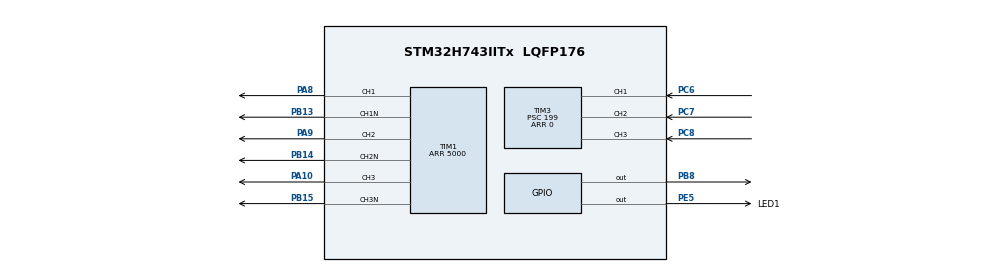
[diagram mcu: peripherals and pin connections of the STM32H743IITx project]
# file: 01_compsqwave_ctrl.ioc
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CORTEX_M7.CPU_DCache=Enabled
CORTEX_M7.CPU_ICache=Enabled
CORTEX_M7.MPU_Control=__NULL
CORTEX_M7.default_mode_Activation=0
Mcu.Family=STM32H7
Mcu.Name=STM32H743IITx
Mcu.Package=LQFP176
NVIC.PriorityGroup=NVIC_PRIORITYGROUP_4
NVIC.TIM3_IRQn=true\:0\:0\:false\:false\:true\:true\:true\:true
PA10.Signal=S_TIM1_CH3
PA13\ (JTMS/SWDIO).Mode=Serial_Wire
PA13\ (JTMS/SWDIO).Signal=DEBUG_JTMS-SWDIO
PA14\ (JTCK/SWCLK).Mode=Serial_Wire
PA14\ (JTCK/SWCLK).Signal=DEBUG_JTCK-SWCLK
PA8.Signal=S_TIM1_CH1
PA9.Signal=S_TIM1_CH2
PB13.Mode=PWM Generation1 CH1 CH1N
PB13.Signal=TIM1_CH1N
PB14.Mode=PWM Generation2 CH2 CH2N
PB14.Signal=TIM1_CH2N
PB15.Mode=PWM Generation3 CH3 CH3N
PB15.Signal=TIM1_CH3N
PB8.Signal=GPIO_Output
PC6.Signal=S_TIM3_CH1
PC7.Signal=S_TIM3_CH2
PC8.Signal=S_TIM3_CH3
PE5.GPIO_Label=LED1
PE5.Signal=GPIO_Output
PH0-OSC_IN\ (PH0).Mode=HSE-External-Oscillator
PH0-OSC_IN\ (PH0).Signal=RCC_OSC_IN
PH1-OSC_OUT\ (PH1).Mode=HSE-External-Oscillator
PH1-OSC_OUT\ (PH1).Signal=RCC_OSC_OUT
ProjectManager.HeapSize=0x200
ProjectManager.StackSize=0x1000
ProjectManager.TargetToolchain=MDK-ARM V5.32
RCC.ADCFreq_Value=50390625
RCC.APB1Freq_Value=100000000
RCC.APB2Freq_Value=100000000
RCC.APB3Freq_Value=100000000
RCC.APB4Freq_Value=100000000
RCC.CortexFreq_Value=400000000
RCC.D1PPRE=RCC_APB3_DIV2
RCC.D2PPRE1=RCC_APB1_DIV2
RCC.D2PPRE2=RCC_APB2_DIV2
RCC.D3PPRE=RCC_APB4_DIV2
RCC.DIVM1=2
RCC.DIVN1=64
RCC.HCLKFreq_Value=200000000
RCC.HPRE=RCC_HCLK_DIV2
RCC.PLLFRACN=0
RCC.PLLSourceVirtual=RCC_PLLSOURCE_HSE
RCC.SYSCLKFreq_VALUE=400000000
RCC.SYSCLKSource=RCC_SYSCLKSOURCE_PLLCLK
RCC.USBFreq_Value=400000000
SH.S_TIM1_CH1.0=TIM1_CH1,PWM Generation1 CH1 CH1N
SH.S_TIM1_CH2.0=TIM1_CH2,PWM Generation2 CH2 CH2N
SH.S_TIM1_CH3.0=TIM1_CH3,PWM Generation3 CH3 CH3N
SH.S_TIM3_CH1.0=TIM3_CH1,Xored_Inputs_Hall_Sensor_Interface
SH.S_TIM3_CH2.0=TIM3_CH2,Xored_Inputs_Hall_Sensor_Interface
SH.S_TIM3_CH3.0=TIM3_CH3,Xored_Inputs_Hall_Sensor_Interface
TIM1.Channel-PWM\ Generation1\ CH1\ CH1N=TIM_CHANNEL_1
TIM1.Channel-PWM\ Generation2\ CH2\ CH2N=TIM_CHANNEL_2
TIM1.Channel-PWM\ Generation3\ CH3\ CH3N=TIM_CHANNEL_3
TIM1.CounterMode=TIM_COUNTERMODE_CENTERALIGNED1
TIM1.DeadTime=0x28
TIM1.OC1Preload_PWM=ENABLE
TIM1.OffStateIDLEMode=TIM_OSSI_ENABLE
TIM1.OffStateRunMode=TIM_OSSR_ENABLE
TIM1.Period=5000
TIM3.Commutation_Delay=3
TIM3.CounterMode=TIM_COUNTERMODE_CENTERALIGNED1
TIM3.IC1Filter=0x0F
TIM3.Period=0
TIM3.Prescaler=199
board=custom

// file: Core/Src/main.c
/* USER CODE BEGIN Header */
/**
  ******************************************************************************
  * @file           : main.c
  * @brief          : Main program body
  ******************************************************************************
  * @attention
  *
  * Copyright (c) 2023 STMicroelectronics.
  * All rights reserved.
  *
  * This software is licensed under terms that can be found in the LICENSE file
  * in the root directory of this software component.
  * If no LICENSE file comes with this software, it is provided AS-IS.
  *
  ******************************************************************************
  */
/* USER CODE END Header */
#include "main.h"
#include "tim.h"
#include "gpio.h"

/* USER CODE BEGIN Includes */
#include "bsp_PMSM.h"
/* USER CODE END Includes */

void SystemClock_Config(void);

int main(void)
{
/* Enable the CPU Cache */

  /* Enable I-Cache---------------------------------------------------------*/
  SCB_EnableICache();

  /* Enable D-Cache---------------------------------------------------------*/
  SCB_EnableDCache();

  /* MCU Configuration--------------------------------------------------------*/

  /* Reset of all peripherals, Initializes the Flash interface and the Systick. */
  HAL_Init();

  /* Configure the system clock */
  SystemClock_Config();

  /* Initialize all configured peripherals */
  MX_GPIO_Init();
  MX_TIM1_Init();
  MX_TIM3_Init();

  /* Infinite loop */
  /* USER CODE BEGIN WHILE */
  PMSMotorStart();
  while (1)
  {
    /* USER CODE END WHILE */

  }
}

void SystemClock_Config(void)
{
  RCC_OscInitTypeDef RCC_OscInitStruct = {0};
  RCC_ClkInitTypeDef RCC_ClkInitStruct = {0};

  /** Supply configuration update enable
  */
  HAL_PWREx_ConfigSupply(PWR_LDO_SUPPLY);

  /** Configure the main internal regulator output voltage
  */
  __HAL_PWR_VOLTAGESCALING_CONFIG(PWR_REGULATOR_VOLTAGE_SCALE1);

  while(!__HAL_PWR_GET_FLAG(PWR_FLAG_VOSRDY)) {}

  /** Initializes the RCC Oscillators according to the specified parameters
  * in the RCC_OscInitTypeDef structure.
  */
  RCC_OscInitStruct.OscillatorType = RCC_OSCILLATORTYPE_HSE;
  RCC_OscInitStruct.HSEState = RCC_HSE_ON;
  RCC_OscInitStruct.PLL.PLLState = RCC_PLL_ON;
  RCC_OscInitStruct.PLL.PLLSource = RCC_PLLSOURCE_HSE;
  RCC_OscInitStruct.PLL.PLLM = 2;
  RCC_OscInitStruct.PLL.PLLN = 64;
  RCC_OscInitStruct.PLL.PLLP = 2;
  RCC_OscInitStruct.PLL.PLLQ = 2;
  RCC_OscInitStruct.PLL.PLLR = 2;
  RCC_OscInitStruct.PLL.PLLRGE = RCC_PLL1VCIRANGE_3;
  RCC_OscInitStruct.PLL.PLLVCOSEL = RCC_PLL1VCOWIDE;
  RCC_OscInitStruct.PLL.PLLFRACN = 0;
  if (HAL_RCC_OscConfig(&RCC_OscInitStruct) != HAL_OK)
  {
    Error_Handler();
  }

  /** Initializes the CPU, AHB and APB buses clocks
  */
  RCC_ClkInitStruct.ClockType = RCC_CLOCKTYPE_HCLK|RCC_CLOCKTYPE_SYSCLK
                              |RCC_CLOCKTYPE_PCLK1|RCC_CLOCKTYPE_PCLK2
                              |RCC_CLOCKTYPE_D3PCLK1|RCC_CLOCKTYPE_D1PCLK1;
  RCC_ClkInitStruct.SYSCLKSource = RCC_SYSCLKSOURCE_PLLCLK;
  RCC_ClkInitStruct.SYSCLKDivider = RCC_SYSCLK_DIV1;
  RCC_ClkInitStruct.AHBCLKDivider = RCC_HCLK_DIV2;
  RCC_ClkInitStruct.APB3CLKDivider = RCC_APB3_DIV2;
  RCC_ClkInitStruct.APB1CLKDivider = RCC_APB1_DIV2;
  RCC_ClkInitStruct.APB2CLKDivider = RCC_APB2_DIV2;
  RCC_ClkInitStruct.APB4CLKDivider = RCC_APB4_DIV2;

  if (HAL_RCC_ClockConfig(&RCC_ClkInitStruct, FLASH_LATENCY_2) != HAL_OK)
  {
    Error_Handler();
  }
}

void Error_Handler(void)
{
  __disable_irq();
  while (1)
  {
  }
}
